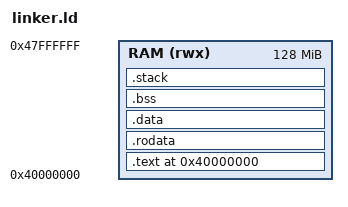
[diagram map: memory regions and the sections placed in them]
ENTRY(_start)

MEMORY
{
    RAM (rwx) : ORIGIN = 0x40000000, LENGTH = 128M
}

SECTIONS
{
    . = 0x40000000;

    .text : {
        KEEP(*(.text.boot))
        *(.text*)
    } > RAM

    .rodata : {
        *(.rodata*)
    } > RAM

    .data : {
        *(.data*)
    } > RAM

    .bss (NOLOAD) : {
        . = ALIGN(16);
        __bss_start = .;
        *(.bss*)
        *(COMMON)
        __bss_end = .;
    } > RAM

    .stack (NOLOAD) : {
        . = ALIGN(64);
        . += 0x8000;
        __forth_dstack_top = .;
        . += 0x8000;
        __forth_rstack_top = .;
    } > RAM
}
